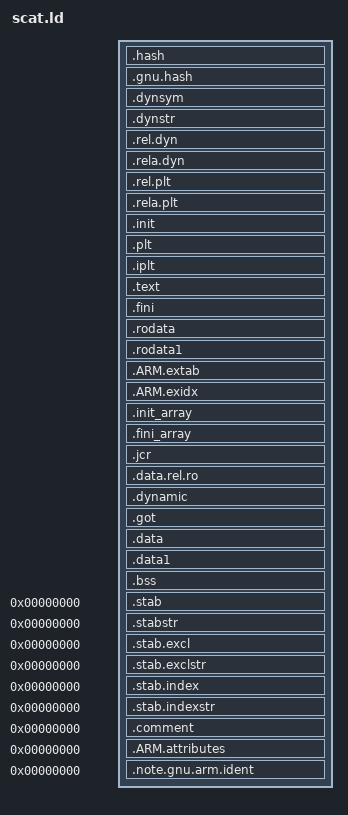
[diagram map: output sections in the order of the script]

/* Script for --shared -z combreloc: shared library, combine & sort relocs */
OUTPUT_FORMAT("elf32-littlearm", "elf32-bigarm",
              "elf32-littlearm")
OUTPUT_ARCH(arm)
ENTRY(gcc_entry)

SECTIONS
{
  /* Read-only sections, merged into text segment: */
  . = SEGMENT_START("text-segment", 0) + SIZEOF_HEADERS;
  .hash           : { *(.hash) }
  .gnu.hash       : { *(.gnu.hash) }
  .dynsym         : { *(.dynsym) }
  .dynstr         : { *(.dynstr) }
  .rel.dyn        :
    {
      *(.rel.init)
      *(.rel.text .rel.text.* .rel.gnu.linkonce.t.*)
      *(.rel.fini)
      *(.rel.rodata .rel.rodata.* .rel.gnu.linkonce.r.*)
      *(.rel.data.rel.ro* .rel.gnu.linkonce.d.rel.ro.*)
      *(.rel.data .rel.data.* .rel.gnu.linkonce.d.*)
      *(.rel.tdata .rel.tdata.* .rel.gnu.linkonce.td.*)
      *(.rel.tbss .rel.tbss.* .rel.gnu.linkonce.tb.*)
      *(.rel.ctors)
      *(.rel.dtors)
      *(.rel.got)
      *(.rel.bss .rel.bss.* .rel.gnu.linkonce.b.*)
      *(.rel.iplt)
    }
  .rela.dyn       :
    {
      *(.rela.init)
      *(.rela.text .rela.text.* .rela.gnu.linkonce.t.*)
      *(.rela.fini)
      *(.rela.rodata .rela.rodata.* .rela.gnu.linkonce.r.*)
      *(.rela.data .rela.data.* .rela.gnu.linkonce.d.*)
      *(.rela.tdata .rela.tdata.* .rela.gnu.linkonce.td.*)
      *(.rela.tbss .rela.tbss.* .rela.gnu.linkonce.tb.*)
      *(.rela.ctors)
      *(.rela.dtors)
      *(.rela.got)
      *(.rela.bss .rela.bss.* .rela.gnu.linkonce.b.*)
      *(.rela.iplt)
    }
  .rel.plt        :
    {
      *(.rel.plt)
    }
  .rela.plt       :
    {
      *(.rela.plt)
    }
  .init           :
  {
    KEEP (*(.init))
  } =0
  .plt            : { *(.plt) }
  .iplt           : { *(.iplt) }
  .text           :
  {
    *(.text.unlikely .text.*_unlikely)
    *(.text .stub .text.* .gnu.linkonce.t.*)
    /* .gnu.warning sections are handled specially by elf32.em.  */
    *(.gnu.warning)
    *(.glue_7t) *(.glue_7) *(.vfp11_veneer) *(.v4_bx)
  } =0
  .fini           :
  {
    KEEP (*(.fini))
  } =0
  PROVIDE (__etext = .);
  PROVIDE (_etext = .);
  PROVIDE (etext = .);
  .rodata         : { *(.rodata .rodata.* .gnu.linkonce.r.*) }
  .rodata1        : { *(.rodata1) }
  .ARM.extab   : { *(.ARM.extab* .gnu.linkonce.armextab.*) }
   PROVIDE_HIDDEN (__exidx_start = .);
  .ARM.exidx   : { *(.ARM.exidx* .gnu.linkonce.armexidx.*) }
   PROVIDE_HIDDEN (__exidx_end = .);
  .init_array     :
  {
    KEEP (*(SORT(.init_array.*)))
    KEEP (*(.init_array))
  }
  .fini_array     :
  {
    KEEP (*(SORT(.fini_array.*)))
    KEEP (*(.fini_array))
  }
  .jcr            : { KEEP (*(.jcr)) }
  .data.rel.ro : { *(.data.rel.ro.local* .gnu.linkonce.d.rel.ro.local.*) *(.data.rel.ro* .gnu.linkonce.d.rel.ro.*) }
  .dynamic        : { *(.dynamic) }
  .got            : { *(.got.plt) *(.igot.plt) *(.got) *(.igot) }
  .data           :
  {
    __data_start = . ;
    *(.data .data.* .gnu.linkonce.d.*)
    SORT(CONSTRUCTORS)
  }
  .data1          : { *(.data1) }
  _edata = .; PROVIDE (edata = .);
  __bss_start = .;
  __bss_start__ = .;
  .bss            :
  {
   *(.dynbss)
   *(.bss .bss.* .gnu.linkonce.b.*)
   *(COMMON)
   /* Align here to ensure that the .bss section occupies space up to
      _end.  Align after .bss to ensure correct alignment even if the
      .bss section disappears because there are no input sections.
      FIXME: Why do we need it? When there is no .bss section, we don't
      pad the .data section.  */
   . = ALIGN(. != 0 ? 32 / 8 : 1);
  }
  _bss_end__ = . ; __bss_end__ = . ;
  . = ALIGN(32 / 8);
  . = ALIGN(32 / 8);
  __end__ = . ;
  _end = .; PROVIDE (end = .);
  /* Stabs debugging sections.  */
  .stab          0 : { *(.stab) }
  .stabstr       0 : { *(.stabstr) }
  .stab.excl     0 : { *(.stab.excl) }
  .stab.exclstr  0 : { *(.stab.exclstr) }
  .stab.index    0 : { *(.stab.index) }
  .stab.indexstr 0 : { *(.stab.indexstr) }
  .comment       0 : { *(.comment) }
  .ARM.attributes 0 : { KEEP (*(.ARM.attributes)) KEEP (*(.gnu.attributes)) }
  .note.gnu.arm.ident 0 : { KEEP (*(.note.gnu.arm.ident)) }
  /DISCARD/ : { *(.note.GNU-stack) *(.gnu_debuglink) *(.gnu.lto_*) }
}
